VERSION ""

NS_ :

BS_:

BU_:

BO_ 2566858996 Basic_Data_1: 8 Vector_XXX
	SG_ SOC : 8|8@1+ (1,0) [0|100] "%" Vector_XXX
	SG_ Current :16|16@1+ (100,5000) [0|10000] "mA" Vector_XXX
	SG_ Voltage: 32|16@1+ (100,0) [0|60000] "mV" Vector_XXX
	SG_ SCD: 48|1@1+ (1,0) [0|1] "" Vector_XXX
	SG_ COV: 49|1@1+ (1,0) [0|1] "" Vector_XXX
	SG_ CUV: 50|1@1+ (1,0) [0|1] "" Vector_XXX
	SG_ OCD: 51|1@1+ (1,0) [0|1] "" Vector_XXX
	SG_ OT: 52|1@1+ (1,0) [0|1] "" Vector_XXX
	SG_ OCC: 53|1@1+ (1,0) [0|1] "" Vector_XXX
	SG_ THERMAL_RUNAWAY: 54|1@1+ (1,0) [0|1] "" Vector_XXX
	SG_ OCDC: 56|1@1+ (1,0) [0|1] "" Vector_XXX
	SG_ UT: 57|1@1+ (1,0) [0|1] "" Vector_XXX
	SG_ OTB: 58|1@1+  (1,0) [0|1] "" Vector_XXX
	SG_ UTB: 59|1@1+ (1,0) [0|1] "" Vector_XXX
	SG_ CELL_CONN: 60|1@1+ (1,0) [0|1] "" Vector_XXX
	SG_ PRL_FAULT: 61|1@1+ (1,0) [0|1] "" Vector_XXX
	SG_ CELL_DIFF: 62|1@1+ (1,0) [0|1] "" Vector_XXX
	SG_ POV: 63|1@1+ (1,0) [0|1] "" Vector_XXX

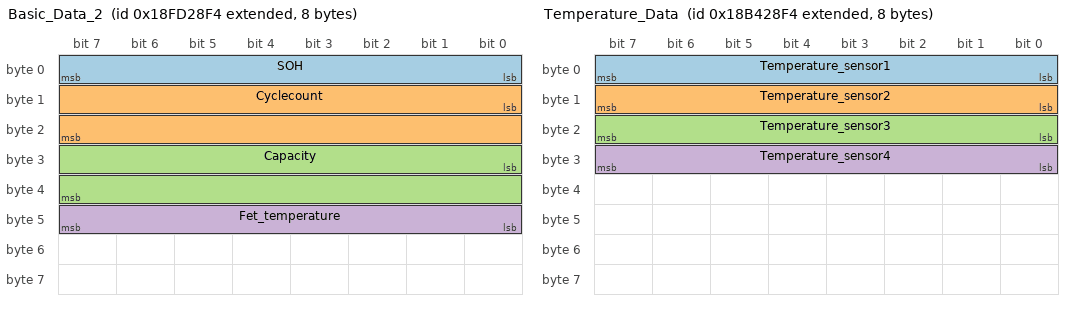
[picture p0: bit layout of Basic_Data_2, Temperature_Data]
BO_ 2566727924 Basic_Data_2: 8 Vector_XXX
	SG_ SOH : 0|8@1+ (1,0) [0|100] "%" Vector_XXX
	SG_ Cyclecount: 8|16@1+ (1, 0) [0|6000] "" Vector_XXX
	SG_ Capacity: 24|16@1+ (1, 0) [0|60000] "Wh" Vector_XXX
	SG_ Fet_temperature: 40|8@1- (1, -40) [-40|120] "°C" Vector_XXX

BO_ 2561943796 Temperature_Data: 8 Vector_XXX
	SG_ Temperature_sensor1: 0|8@1- (1, -40) [-40|120] "°C" Vector_XXX
	SG_ Temperature_sensor2: 8|8@1- (1, -40) [-40|120] "°C" Vector_XXX
	SG_ Temperature_sensor3: 16|8@1- (1, -40) [-40|120] "°C" Vector_XXX
	SG_ Temperature_sensor4: 24|8@1- (1, -40) [-40|120] "°C" Vector_XXX

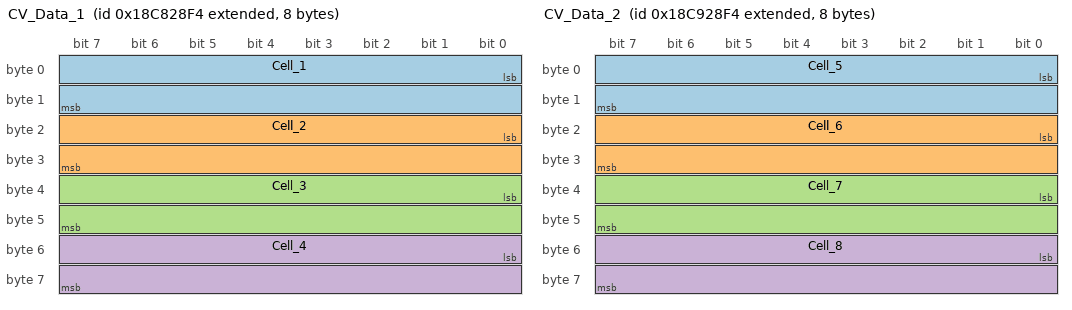
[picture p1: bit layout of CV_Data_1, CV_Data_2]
BO_ 2563254516 CV_Data_1: 8 Vector_XXX
	SG_ Cell_1: 0|16@1+ (1, 0) [0|6000] "mV" Vector_XXX
	SG_ Cell_2: 16|16@1+ (1, 0) [0|6000] "mV" Vector_XXX
	SG_ Cell_3: 32|16@1+ (1, 0) [0|6000] "mV" Vector_XXX
	SG_ Cell_4: 48|16@1+ (1, 0) [0|6000] "mV" Vector_XXX

BO_ 2563320052 CV_Data_2: 8 Vector_XXX
	SG_ Cell_5: 0|16@1+ (1, 0) [0|6000] "mV" Vector_XXX
	SG_ Cell_6: 16|16@1+ (1, 0) [0|6000] "mV" Vector_XXX
	SG_ Cell_7: 32|16@1+ (1, 0) [0|6000] "mV" Vector_XXX
	SG_ Cell_8: 48|16@1+ (1, 0) [0|6000] "mV" Vector_XXX

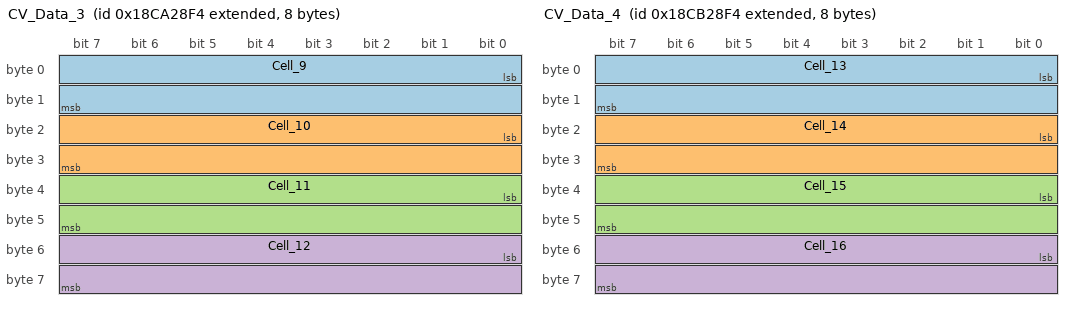
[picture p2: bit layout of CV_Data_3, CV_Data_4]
BO_ 2563385588 CV_Data_3: 8 Vector_XXX
	SG_ Cell_9: 0|16@1+ (1, 0) [0|6000] "mV" Vector_XXX
	SG_ Cell_10: 16|16@1+ (1, 0) [0|6000] "mV" Vector_XXX
	SG_ Cell_11: 32|16@1+ (1, 0) [0|6000] "mV" Vector_XXX
	SG_ Cell_12: 48|16@1+ (1, 0) [0|6000] "mV" Vector_XXX

BO_ 2563451124 CV_Data_4: 8 Vector_XXX
	SG_ Cell_13: 0|16@1+ (1, 0) [0|6000] "mV" Vector_XXX
	SG_ Cell_14: 16|16@1+ (1, 0) [0|6000] "mV" Vector_XXX
	SG_ Cell_15: 32|16@1+ (1, 0) [0|6000] "mV" Vector_XXX
	SG_ Cell_16: 48|16@1+ (1, 0) [0|6000] "mV" Vector_XXX
